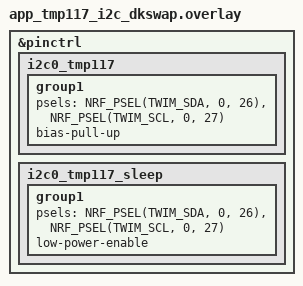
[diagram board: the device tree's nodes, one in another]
/*
 * Optional: nRF52840 DK Arduino order **SDA=P0.26, SCL=P0.27** (D14/D15).
 * Append **after** app_tmp117_i2c.overlay:
 *
 *   -DDTC_OVERLAY_FILE="app_tmp117_i2c.overlay;app_tmp117_i2c_dkswap.overlay"
 */

#include <zephyr/dt-bindings/pinctrl/nrf-pinctrl.h>

&pinctrl {
	i2c0_tmp117: i2c0_tmp117 {
		group1 {
			psels = <NRF_PSEL(TWIM_SDA, 0, 26)>,
				<NRF_PSEL(TWIM_SCL, 0, 27)>;
			bias-pull-up;
		};
	};

	i2c0_tmp117_sleep: i2c0_tmp117_sleep {
		group1 {
			psels = <NRF_PSEL(TWIM_SDA, 0, 26)>,
				<NRF_PSEL(TWIM_SCL, 0, 27)>;
			low-power-enable;
		};
	};
};
